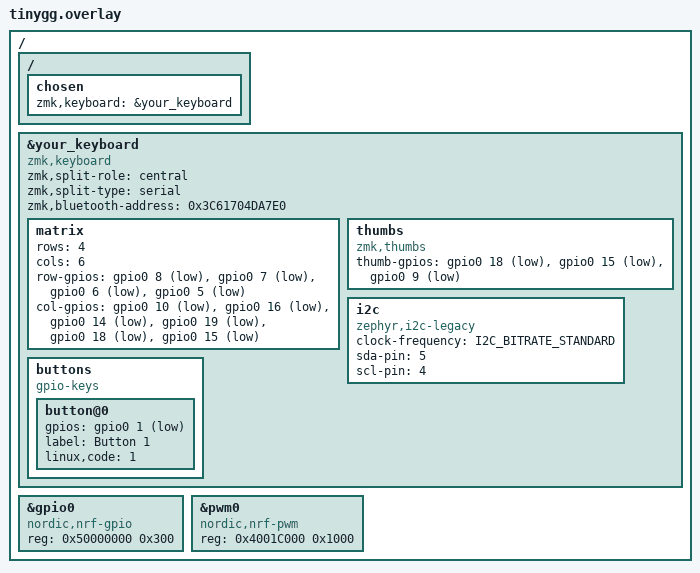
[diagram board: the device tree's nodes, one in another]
/dts-v1/;
/ {
    / {
        chosen {
            zmk,keyboard = &your_keyboard;
        };
    };

    &your_keyboard {
        compatible = "zmk,keyboard";
        zmk,split-role = "central";
        zmk,split-type = "serial";
        zmk,bluetooth-address = <0x3C61704DA7E0>;

        // Define the key matrix
        matrix {
            rows = <4>;
            cols = <6>;

            row-gpios = <&gpio0 8 GPIO_ACTIVE_LOW>,  // Bottom row, P8
                        <&gpio0 7 GPIO_ACTIVE_LOW>,  // Home row, P7
                        <&gpio0 6 GPIO_ACTIVE_LOW>,  // Top row, P6
                        <&gpio0 5 GPIO_ACTIVE_LOW>;  // Num row, P5

            col-gpios = <&gpio0 10 GPIO_ACTIVE_LOW>, // Outer column, P10
                        <&gpio0 16 GPIO_ACTIVE_LOW>, // Pinky column, P16
                        <&gpio0 14 GPIO_ACTIVE_LOW>, // Ring column, P14
                        <&gpio0 19 GPIO_ACTIVE_LOW>, // Middle column, P19
                        <&gpio0 18 GPIO_ACTIVE_LOW>, // Index column, P18
                        <&gpio0 15 GPIO_ACTIVE_LOW>; // Inner column, P15
        };

        // Thumb keys definition
        thumbs {
            compatible = "zmk,thumbs";
            thumb-gpios = <&gpio0 18 GPIO_ACTIVE_LOW>,  // Layer key, P18
                          <&gpio0 15 GPIO_ACTIVE_LOW>,  // Space key, P15
                          <&gpio0 9 GPIO_ACTIVE_LOW>;   // Cluster key, P9
        };

        // Optional: Define additional peripherals if any
        i2c {
            compatible = "zephyr,i2c-legacy";
            clock-frequency = <I2C_BITRATE_STANDARD>;
            sda-pin = <5>;
            scl-pin = <4>;
        };

        // Optional: Define any buttons or other peripherals
        buttons {
            compatible = "gpio-keys";
            button@0 {
                gpios = <&gpio0 1 GPIO_ACTIVE_LOW>;
                label = "Button 1";
                linux,code = <1>;
            };
        };
    };

    &gpio0 {
        compatible = "nordic,nrf-gpio";
        reg = <0x50000000 0x300>;
    };

    &pwm0 {
        compatible = "nordic,nrf-pwm";
        reg = <0x4001C000 0x1000>;
    };
};
